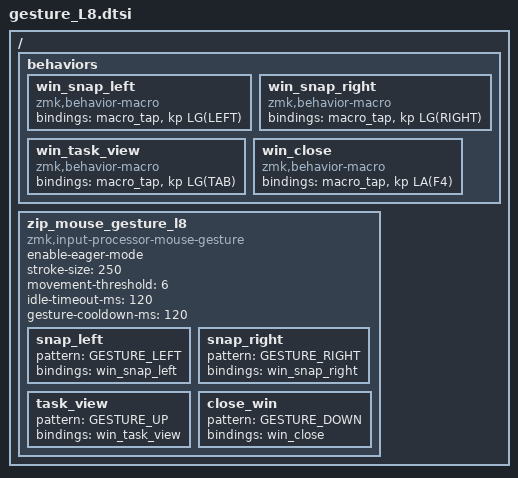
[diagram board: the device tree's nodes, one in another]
#include <behaviors.dtsi>
#include <dt-bindings/zmk/keys.h>

/ {
  behaviors {
    win_snap_left: win_snap_left {
      compatible = "zmk,behavior-macro";
      #binding-cells = <0>;
      bindings = <&macro_tap &kp LG(LEFT)>;
    };

    win_snap_right: win_snap_right {
      compatible = "zmk,behavior-macro";
      #binding-cells = <0>;
      bindings = <&macro_tap &kp LG(RIGHT)>;
    };

    win_task_view: win_task_view {
      compatible = "zmk,behavior-macro";
      #binding-cells = <0>;
      bindings = <&macro_tap &kp LG(TAB)>;
    };

    win_close: win_close {
      compatible = "zmk,behavior-macro";
      #binding-cells = <0>;
      bindings = <&macro_tap &kp LA(F4)>;
    };
  };

  zip_mouse_gesture_l8: zip_mouse_gesture_l8 {
    compatible = "zmk,input-processor-mouse-gesture";
    #input-processor-cells = <0>;

    enable-eager-mode;
    stroke-size = <250>;
    movement-threshold = <6>;
    idle-timeout-ms = <120>;
    gesture-cooldown-ms = <120>;

    snap_left   { pattern = <GESTURE_LEFT>;  bindings = <&win_snap_left>; };
    snap_right  { pattern = <GESTURE_RIGHT>; bindings = <&win_snap_right>; };
    task_view   { pattern = <GESTURE_UP>;    bindings = <&win_task_view>; };
    close_win   { pattern = <GESTURE_DOWN>;  bindings = <&win_close>; };
  };
};
